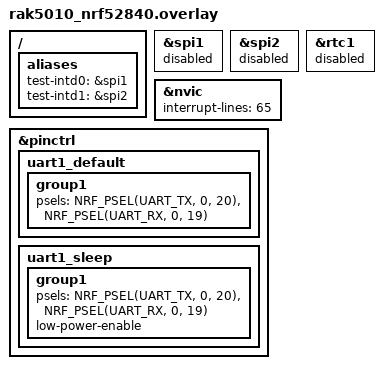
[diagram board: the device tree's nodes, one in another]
/*
 * Copyright (c) 2024 Nordic Semiconductor
 *
 * SPDX-License-Identifier: Apache-2.0
 */

/ {
	aliases {
		test-intd0 = &spi1;
		test-intd1 = &spi2;
	};
};

&spi1 {
	status = "reserved";
};

&spi2 {
	status = "reserved";
};

&rtc1 {
	status = "reserved";
};

&nvic {
	interrupt-lines = <65>;
};

/* Console routed to IO1 and IO2 */
&pinctrl {
	uart1_default: uart1_default {
		group1 {
			psels = <NRF_PSEL(UART_TX, 0, 20)>,
				<NRF_PSEL(UART_RX, 0, 19)>;
		};
	};

	uart1_sleep: uart1_sleep {
		group1 {
			psels = <NRF_PSEL(UART_TX, 0, 20)>,
				<NRF_PSEL(UART_RX, 0, 19)>;
			low-power-enable;
		};
	};
};
